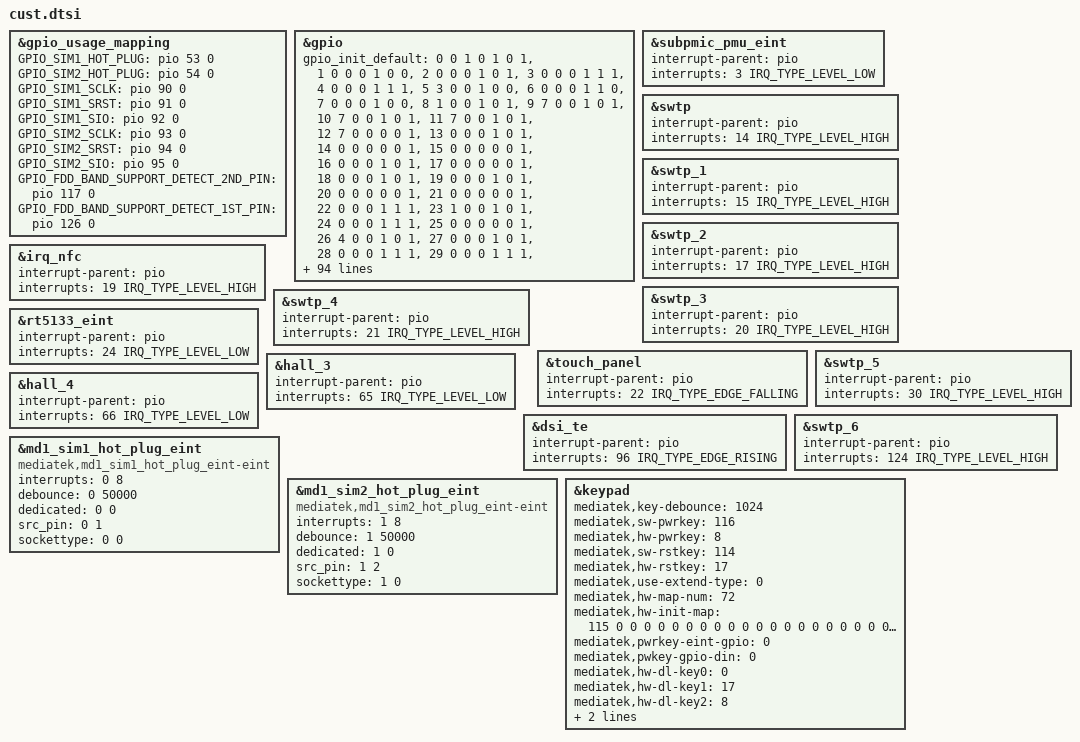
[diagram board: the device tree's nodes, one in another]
/*
 * Generated by MTK SP DrvGen Version: 3.5.160809 for MT6879.
 * Do Not Modify The File.
 * Copyright Mediatek Inc. (c) 2016.
 */

/*************************
 * ADC DTSI File
 *************************/



/*************************
 * CLK_BUF DTSI File
 *************************/



/*************************
 * I2C DTSI File
 *************************/



/*************************
 * GPIO DTSI File
 *************************/

&gpio_usage_mapping {
	GPIO_SIM1_HOT_PLUG = <&pio 53 0>;
	GPIO_SIM2_HOT_PLUG = <&pio 54 0>;
	GPIO_SIM1_SCLK = <&pio 90 0>;
	GPIO_SIM1_SRST = <&pio 91 0>;
	GPIO_SIM1_SIO = <&pio 92 0>;
	GPIO_SIM2_SCLK = <&pio 93 0>;
	GPIO_SIM2_SRST = <&pio 94 0>;
	GPIO_SIM2_SIO = <&pio 95 0>;
	GPIO_FDD_BAND_SUPPORT_DETECT_2ND_PIN = <&pio 117 0>;
	GPIO_FDD_BAND_SUPPORT_DETECT_1ST_PIN = <&pio 126 0>;
};

&gpio {
	gpio_init_default =
		<0 0 1 0 1 0 1>,
		<1 0 0 0 1 0 0>,
		<2 0 0 0 1 0 1>,
		<3 0 0 0 1 1 1>,
		<4 0 0 0 1 1 1>,
		<5 3 0 0 1 0 0>,
		<6 0 0 0 1 1 0>,
		<7 0 0 0 1 0 0>,
		<8 1 0 0 1 0 1>,
		<9 7 0 0 1 0 1>,
		<10 7 0 0 1 0 1>,
		<11 7 0 0 1 0 1>,
		<12 7 0 0 0 0 1>,
		<13 0 0 0 1 0 1>,
		<14 0 0 0 0 0 1>,
		<15 0 0 0 0 0 1>,
		<16 0 0 0 1 0 1>,
		<17 0 0 0 0 0 1>,
		<18 0 0 0 1 0 1>,
		<19 0 0 0 1 0 1>,
		<20 0 0 0 0 0 1>,
		<21 0 0 0 0 0 1>,
		<22 0 0 0 1 1 1>,
		<23 1 0 0 1 0 1>,
		<24 0 0 0 1 1 1>,
		<25 0 0 0 0 0 1>,
		<26 4 0 0 1 0 1>,
		<27 0 0 0 1 0 1>,
		<28 0 0 0 1 1 1>,
		<29 0 0 0 1 1 1>,
		<30 0 0 0 0 0 1>,
		<31 0 0 0 1 1 1>,
		<32 0 1 0 1 0 1>,
		<33 0 1 0 1 0 1>,
		<34 0 0 0 1 0 1>,
		<35 0 0 0 1 0 1>,
		<36 1 0 0 0 0 1>,
		<37 1 0 0 0 0 1>,
		<38 1 0 0 0 0 1>,
		<39 3 0 0 1 0 1>,
		<40 1 0 0 1 0 1>,
		<41 1 0 0 1 0 1>,
		<42 1 0 0 1 0 1>,
		<43 1 0 0 1 0 1>,
		<44 1 0 0 1 0 1>,
		<45 1 0 0 1 0 1>,
		<46 1 0 0 1 0 1>,
		<47 1 0 0 1 0 1>,
		<48 6 0 0 1 0 1>,
		<49 6 0 0 1 0 1>,
		<50 6 0 0 1 0 1>,
		<51 6 0 0 1 0 1>,
		<52 6 0 0 1 0 1>,
		<53 1 0 0 1 1 1>,
		<54 1 0 0 1 1 1>,
		<55 1 0 0 1 0 1>,
		<56 1 0 0 1 1 1>,
		<57 2 0 0 1 0 1>,
		<58 2 0 0 1 1 1>,
		<59 0 1 0 1 0 1>,
		<60 0 1 0 1 0 1>,
		<61 1 0 0 1 1 1>,
		<62 0 0 0 1 1 1>,
		<63 1 0 0 0 0 1>,
		<64 1 0 0 0 0 1>,
		<65 1 0 0 0 0 1>,
		<66 1 0 0 1 0 1>,
		<67 2 0 0 0 0 1>,
		<68 2 0 0 0 0 1>,
		<69 2 0 0 0 0 1>,
		<70 2 0 0 1 0 1>,
		<71 1 0 0 0 0 1>,
		<72 1 0 0 0 0 1>,
		<73 1 0 0 0 0 1>,
		<74 1 0 0 1 0 1>,
		<75 2 0 0 0 0 1>,
		<76 2 0 0 0 0 1>,
		<77 2 0 0 0 0 1>,
		<78 2 0 0 1 0 1>,
		<79 0 0 0 1 0 0>,
		<80 0 0 0 1 0 0>,
		<81 0 0 0 1 0 0>,
		<82 0 0 0 1 0 0>,
		<83 0 0 0 1 0 0>,
		<84 1 0 0 0 0 1>,
		<85 1 0 0 1 1 1>,
		<86 1 0 0 1 1 1>,
		<87 1 0 0 1 1 1>,
		<88 1 0 0 1 1 1>,
		<89 1 0 0 1 1 1>,
		<90 1 0 0 0 0 1>,
		<91 1 0 0 0 0 1>,
		<92 1 0 0 1 1 1>,
		<93 1 0 0 0 0 1>,
		<94 1 0 0 0 0 1>,
		<95 1 0 0 1 1 1>,
		<96 1 0 0 1 0 1>,
		<97 0 0 0 0 0 1>,
		<98 0 1 0 1 0 1>,
		<99 1 0 0 0 0 1>,
		<100 1 0 0 0 0 1>,
		<101 1 0 0 0 0 1>,
		<102 1 0 0 0 0 1>,
		<103 0 1 0 1 0 1>,
		<104 0 1 0 1 0 1>,
		<105 1 0 0 1 0 1>,
		<106 1 0 0 1 0 1>,
		<107 0 0 0 1 0 0>,
		<108 1 0 0 0 0 1>,
		<109 1 0 0 0 0 1>,
		<110 1 0 0 0 0 1>,
		<111 1 0 0 0 0 1>,
		<112 1 0 0 0 0 1>,
		<113 1 0 0 0 0 1>,
		<114 1 0 0 0 0 1>,
		<115 1 0 0 0 0 1>,
		<116 1 0 0 0 0 1>,
		<117 0 0 0 1 1 0>,
		<118 1 0 0 0 0 1>,
		<119 1 0 0 0 0 1>,
		<120 0 1 0 1 0 1>,
		<121 0 1 0 1 0 1>,
		<122 0 0 0 1 1 0>,
		<123 3 0 0 1 0 0>,
		<124 0 0 0 0 0 1>,
		<125 1 0 0 0 0 1>,
		<126 0 0 0 1 0 0>,
		<127 1 0 0 0 0 1>,
		<128 1 0 0 0 0 1>,
		<129 1 0 0 0 0 0>,
		<130 1 0 0 1 0 0>,
		<131 1 0 0 0 0 0>,
		<132 1 0 0 1 0 0>,
		<133 1 0 0 0 0 0>,
		<134 1 0 0 1 0 0>,
		<135 0 1 0 1 0 1>,
		<136 0 1 0 1 0 1>,
		<137 1 0 0 1 0 1>,
		<138 1 0 0 1 0 1>,
		<139 1 0 0 1 1 1>,
		<140 1 0 0 1 1 1>,
		<141 2 0 0 1 1 1>,
		<142 2 0 0 1 1 1>,
		<143 1 0 0 1 1 1>,
		<144 1 0 0 1 1 1>,
		<145 1 0 0 1 1 1>,
		<146 1 0 0 1 1 1>,
		<147 1 0 0 1 1 1>,
		<148 1 0 0 1 1 1>,
		<149 1 0 0 1 1 1>,
		<150 1 0 0 1 1 1>,
		<151 1 0 0 1 1 1>,
		<152 1 0 0 1 1 1>,
		<153 1 0 0 1 1 1>,
		<154 1 0 0 1 1 1>,
		<155 1 0 0 1 1 1>,
		<156 1 0 0 1 1 1>,
		<157 3 0 0 1 1 1>,
		<158 3 0 0 1 1 1>,
		<159 0 1 0 1 0 1>,
		<160 0 1 0 1 0 1>,
		<161 0 0 0 1 0 1>,
		<162 0 1 0 1 0 1>,
		<163 0 1 0 1 0 1>,
		<164 0 0 0 1 0 1>,
		<165 0 0 0 1 0 1>,
		<166 0 0 0 1 0 1>,
		<167 0 0 0 1 0 1>,
		<168 0 1 0 1 0 1>,
		<169 1 0 0 0 0 1>,
		<170 1 0 0 0 0 1>,
		<171 1 0 0 0 0 1>,
		<172 1 0 0 0 0 1>,
		<173 1 0 0 0 0 1>,
		<174 1 0 0 0 0 1>,
		<175 1 0 0 0 0 1>,
		<176 1 0 0 1 0 1>,
		<177 1 0 0 0 0 1>,
		<178 1 0 0 0 0 1>,
		<179 1 0 0 0 0 1>,
		<180 1 0 0 0 0 1>,
		<181 1 0 0 0 0 1>,
		<182 1 0 0 0 0 1>,
		<183 0 0 0 1 1 1>,
		<184 1 0 0 0 0 1>,
		<185 1 0 0 1 0 1>,
		<186 1 0 0 1 0 1>,
		<187 1 0 0 1 0 1>,
		<188 0 1 0 1 0 1>,
		<189 0 0 0 1 0 0>,
		<190 0 0 0 1 0 1>,
		<191 0 0 0 1 0 1>,
		<192 0 0 0 1 0 1>,
		<193 0 0 0 1 0 1>,
		<194 0 0 0 1 0 1>,
		<195 0 0 0 1 0 1>,
		<196 0 0 0 1 0 1>,
		<197 0 0 0 1 0 1>,
		<198 0 0 0 1 0 1>,
		<199 0 0 0 1 0 1>,
		<200 0 0 0 1 0 1>,
		<201 0 1 1 1 0 1>,
		<202 1 0 0 0 0 1>,
		<203 1 0 0 0 0 1>,
		<204 1 0 0 1 0 1>,
		<205 1 0 0 1 0 1>,
		<206 1 0 0 1 0 1>,
		<207 1 0 0 1 0 1>,
		<208 1 0 0 0 0 1>,
		<209 1 0 0 0 0 1>,
		<210 1 0 0 0 0 1>,
		<211 1 0 0 1 0 1>,
		<212 1 0 0 1 0 1>,
		<213 1 0 0 1 0 1>,
		<214 1 0 0 0 0 1>,
		<215 1 0 0 0 0 1>,
		<216 1 0 0 1 0 1>;
};


/*************************
 * EINT DTSI File
 *************************/

#include <dt-bindings/interrupt-controller/irq.h>
#include <dt-bindings/interrupt-controller/arm-gic.h>

&subpmic_pmu_eint {
	interrupt-parent = <&pio>;
	interrupts = <3 IRQ_TYPE_LEVEL_LOW>;
	status = "okay";
};

&swtp {
	interrupt-parent = <&pio>;
	interrupts = <14 IRQ_TYPE_LEVEL_HIGH>;
	status = "okay";
};

&swtp_1 {
	interrupt-parent = <&pio>;
	interrupts = <15 IRQ_TYPE_LEVEL_HIGH>;
	status = "okay";
};

&swtp_2 {
	interrupt-parent = <&pio>;
	interrupts = <17 IRQ_TYPE_LEVEL_HIGH>;
	status = "okay";
};

&irq_nfc {
	interrupt-parent = <&pio>;
	interrupts = <19 IRQ_TYPE_LEVEL_HIGH>;
	status = "okay";
};

&swtp_3 {
	interrupt-parent = <&pio>;
	interrupts = <20 IRQ_TYPE_LEVEL_HIGH>;
	status = "okay";
};

&swtp_4 {
	interrupt-parent = <&pio>;
	interrupts = <21 IRQ_TYPE_LEVEL_HIGH>;
	status = "okay";
};

&touch_panel {
	interrupt-parent = <&pio>;
	interrupts = <22 IRQ_TYPE_EDGE_FALLING>;
	status = "okay";
};

&rt5133_eint {
	interrupt-parent = <&pio>;
	interrupts = <24 IRQ_TYPE_LEVEL_LOW>;
	status = "okay";
};

&swtp_5 {
	interrupt-parent = <&pio>;
	interrupts = <30 IRQ_TYPE_LEVEL_HIGH>;
	status = "okay";
};

&hall_3 {
	interrupt-parent = <&pio>;
	interrupts = <65 IRQ_TYPE_LEVEL_LOW>;
	status = "okay";
};

&hall_4 {
	interrupt-parent = <&pio>;
	interrupts = <66 IRQ_TYPE_LEVEL_LOW>;
	status = "okay";
};

&dsi_te {
	interrupt-parent = <&pio>;
	interrupts = <96 IRQ_TYPE_EDGE_RISING>;
	status = "okay";
};

&swtp_6 {
	interrupt-parent = <&pio>;
	interrupts = <124 IRQ_TYPE_LEVEL_HIGH>;
	status = "okay";
};

&md1_sim1_hot_plug_eint {
	compatible = "mediatek,md1_sim1_hot_plug_eint-eint";
	interrupts = <0 IRQ_TYPE_LEVEL_LOW>;
	debounce = <0 50000>;
	dedicated = <0 0>;
	src_pin = <0 1>;
	sockettype = <0 0>;
	status = "okay";
};

&md1_sim2_hot_plug_eint {
	compatible = "mediatek,md1_sim2_hot_plug_eint-eint";
	interrupts = <1 IRQ_TYPE_LEVEL_LOW>;
	debounce = <1 50000>;
	dedicated = <1 0>;
	src_pin = <1 2>;
	sockettype = <1 0>;
	status = "okay";
};


/*************************
 * MD1_EINT DTSI File
 *************************/

&md1_sim1_hot_plug_eint {
	compatible = "mediatek,md1_sim1_hot_plug_eint-eint";
	interrupts = <0 8>;
	debounce = <0 50000>;
	dedicated = <0 0>;
	src_pin = <0 1>;
	sockettype = <0 0>;
	status = "okay";
};

&md1_sim2_hot_plug_eint {
	compatible = "mediatek,md1_sim2_hot_plug_eint-eint";
	interrupts = <1 8>;
	debounce = <1 50000>;
	dedicated = <1 0>;
	src_pin = <1 2>;
	sockettype = <1 0>;
	status = "okay";
};


/*************************
 * PMIC DTSI File
 *************************/



/*************************
 * POWER DTSI File
 *************************/



/*************************
 * KPD DTSI File
 *************************/

&keypad {
	mediatek,key-debounce = <1024>;
	mediatek,sw-pwrkey = <116>;
	mediatek,hw-pwrkey = <8>;
	mediatek,sw-rstkey = <114>;
	mediatek,hw-rstkey = <17>;
	mediatek,use-extend-type = <0>;
	/*HW Keycode [0~71] -> Linux Keycode*/
	mediatek,hw-map-num = <72>;
	mediatek,hw-init-map = <115 0 0 0 0 0 0 0 0 0 0 0 0 0 0 0 0 0 0 0 0 0 0 0 0 0 0 0 0 0 0 0 0 0 0 0 0 0 0 0 0 0 0 0 0 0 0 0 0 0 0 0 0 0 0 0 0 0 0 0 0 0 0 0 0 0 0 0 0 0 0 0 >;
	mediatek,pwrkey-eint-gpio = <0>;
	mediatek,pwkey-gpio-din = <0>;
	mediatek,hw-dl-key0 = <0>;
	mediatek,hw-dl-key1 = <17>;
	mediatek,hw-dl-key2 = <8>;
	mediatek,hw-recovery-key = <0>;
	mediatek,hw-factory-key = <17>;
	status = "okay";
};
